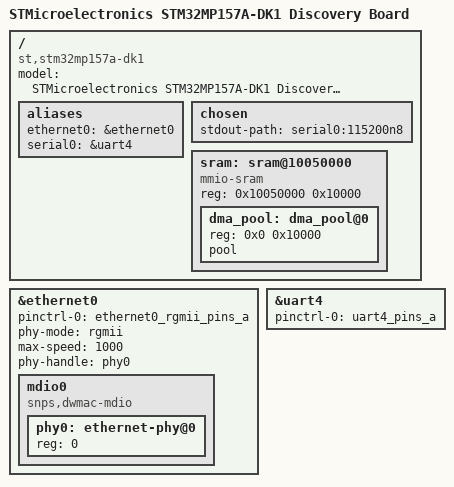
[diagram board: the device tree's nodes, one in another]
// SPDX-License-Identifier: (GPL-2.0+ OR BSD-3-Clause)
/*
 * Copyright (C) STMicroelectronics 2018 - All Rights Reserved
 * Author: Alexandre Torgue <alexandre.torgue@st.com>.
 */

/dts-v1/;

#include "stm32mp157c.dtsi"
#include <arm/stm32mp157c.dtsi>
#include <arm/stm32mp157-pinctrl.dtsi>

/ {
	model = "STMicroelectronics STM32MP157A-DK1 Discovery Board";
	compatible = "st,stm32mp157a-dk1", "st,stm32mp157";

	aliases {
		ethernet0 = &ethernet0;
		serial0 = &uart4;
	};

	chosen {
		stdout-path = "serial0:115200n8";
	};

	sram: sram@10050000 {
		compatible = "mmio-sram";
		reg = <0x10050000 0x10000>;
		#address-cells = <1>;
		#size-cells = <1>;
		ranges = <0 0x10050000 0x10000>;

		dma_pool: dma_pool@0 {
			reg = <0x0 0x10000>;
			pool;
		};
	};
};

&ethernet0 {
	status = "okay";
	pinctrl-0 = <&ethernet0_rgmii_pins_a>;
	pinctrl-names = "default", "sleep";
	phy-mode = "rgmii";
	max-speed = <1000>;
	phy-handle = <&phy0>;

	mdio0 {
		#address-cells = <1>;
		#size-cells = <0>;
		compatible = "snps,dwmac-mdio";
		phy0: ethernet-phy@0 {
			reg = <0>;
		};
	};
};

&uart4 {
	pinctrl-names = "default";
	pinctrl-0 = <&uart4_pins_a>;
	status = "okay";
};
